# ATmega2560 register map
Vendor: Atmel; File version: 1.0
CPU: other r0p0, little endian, no MPU, no FPU, 4 interrupt priority bits
Registers are 8-bit, read-write, reset 0x0 unless marked. A register's access mark holds for its fields unless they carry their own. Offsets are from the block's base; [hi:lo] are bit positions; {n}, {i} and the like mark numbered series.

## AC — Analog Comparator
Base 0x00000050
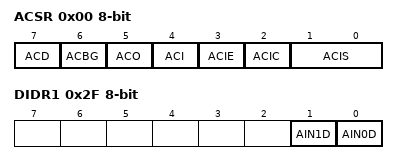
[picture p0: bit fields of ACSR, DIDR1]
0x00 ACSR — Analog Comparator Control And Status Register
  [7] ACD — Analog Comparator Disable
  [6] ACBG — Analog Comparator Bandgap Select
  [5] ACO ro — Analog Compare Output
  [4] ACI — Analog Comparator Interrupt Flag
  [3] ACIE — Analog Comparator Interrupt Enable
  [2] ACIC — Analog Comparator Input Capture Enable
  [1:0] ACIS — Analog Comparator Interrupt Mode Select
    0=ON_TOGGLE (Interrupt on Toggle); 2=ON_FALLING_EDGE (Interrupt on Falling Edge); 3=ON_RISING_EDGE (Interrupt on Rising Edge)
0x2B ADCSRB — ADC Control and Status Register B
  [6] ACME — Analog Comparator Multiplexer Enable
0x2F DIDR1 — Digital Input Disable Register 1
  [1] AIN1D — AIN1 Digital Input Disable
  [0] AIN0D — AIN0 Digital Input Disable

## ADC — Analog-to-Digital Converter
Base 0x00000078
0x00 ADC 16-bit (reset mask 0xFF) — ADC Data Register Bytes
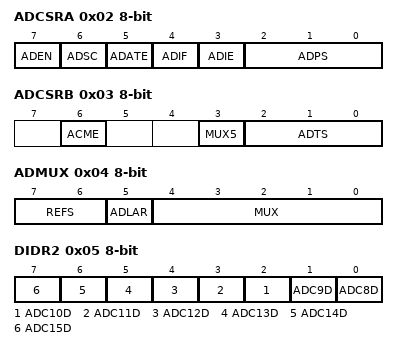
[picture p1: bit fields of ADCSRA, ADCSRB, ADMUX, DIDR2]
0x02 ADCSRA — The ADC Control and Status register A
  [7] ADEN — ADC Enable
  [6] ADSC — ADC Start Conversion
  [5] ADATE — ADC Auto Trigger Enable
  [4] ADIF — ADC Interrupt Flag
  [3] ADIE — ADC Interrupt Enable
  [2:0] ADPS — ADC Prescaler Select Bits
    1=PRESCALER_2 (Prescaler Value 2); 2=PRESCALER_4 (Prescaler Value 4); 3=PRESCALER_8 (Prescaler Value 8); 4=PRESCALER_16 (Prescaler Value 16); 5=PRESCALER_32 (Prescaler Value 32); 6=PRESCALER_64 (Prescaler Value 64); 7=PRESCALER_128 (Prescaler Value 128)
0x03 ADCSRB — The ADC Control and Status register B
  [6] ACME
  [3] MUX5 — Analog Channel and Gain Selection Bits
  [2:0] ADTS — ADC Auto Trigger Source bits
    0=Free Running mode; 1=Analog Comparator; 2=External Interrupt Request 0; 3=Timer/Counter0 Compare Match A; 4=Timer/Counter0 Overflow; 5=Timer/Counter1 Compare Match B; 6=Timer/Counter1 Overflow; 7=Timer/Counter1 Capture Event
0x04 ADMUX — The ADC multiplexer Selection Register
  [7:6] REFS — Reference Selection Bits
    0=AREF (Aref Internal Vref turned off); 1=AVCC (AVcc with external capacitor at AREF pin); 3=INTERNAL (Internal 1.1V Voltage Reference with external capacitor at AREF pin)
  [5] ADLAR — Left Adjust Result
  [4:0] MUX — Analog Channel and Gain Selection Bits
    {v}=ADC{v} (ADC Single Ended Input pin {v}) (v=0..7); 8=ADC0_ADC0_10X (ADC Differential Inputs Postive pin 0 Negative pin 0 10x Gain); 9=ADC1_ADC0_10X (ADC Differential Inputs Postive pin 1 Negative pin 0 10x Gain); 10=ADC0_ADC0_200x (ADC Differential Inputs Postive pin 0 Negative pin 0 200x Gain); 11=ADC1_ADC0_200X (ADC Differential Inputs Postive pin 1 Negative pin 0 200x Gain); 12=ADC2_ADC2_10X (ADC Differential Inputs Postive pin 2 Negative pin 2 10x Gain); 13=ADC3_ADC2_10X (ADC Differential Inputs Postive pin 3 Negative pin 2 10x Gain); 14=ADC2_ADC2_200X (ADC Differential Inputs Postive pin 2 Negative pin 2 200x Gain); 15=ADC3_ADC2_200X (ADC Differential Inputs Postive pin 3 Negative pin 2 200x Gain); {v}=ADC{v-16}_ADC1_1X (ADC Differential Inputs Postive pin {v-16} Negative pin 1 1x Gain) (v=16..23); {v}=ADC{v-24}_ADC2_1X (ADC Differential Inputs Postive pin {v-24} Negative pin 2 1x Gain) (v=24..29); 30=ADC_VBG (Internal Reference (VBG)); 31=ADC_GND (0V (GND))
0x05 DIDR2 — Digital Input Disable Register
  [n-8] ADC{n}D (n=8..15)
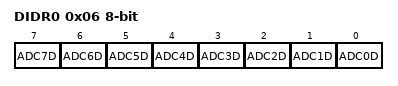
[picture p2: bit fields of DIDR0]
0x06 DIDR0 — Digital Input Disable Register
  [n] ADC{n}D (n=0..7)

## BOOT_LOAD — Bootloader
Base 0x00000057
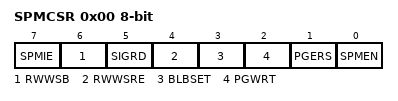
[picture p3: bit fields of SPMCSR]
0x00 SPMCSR — Store Program Memory Control Register
  [7] SPMIE — SPM Interrupt Enable
  [6] RWWSB — Read While Write Section Busy
  [5] SIGRD — Signature Row Read
  [4] RWWSRE — Read While Write section read enable
  [3] BLBSET — Boot Lock Bit Set
  [2] PGWRT — Page Write
  [1] PGERS — Page Erase
  [0] SPMEN — Store Program Memory Enable
